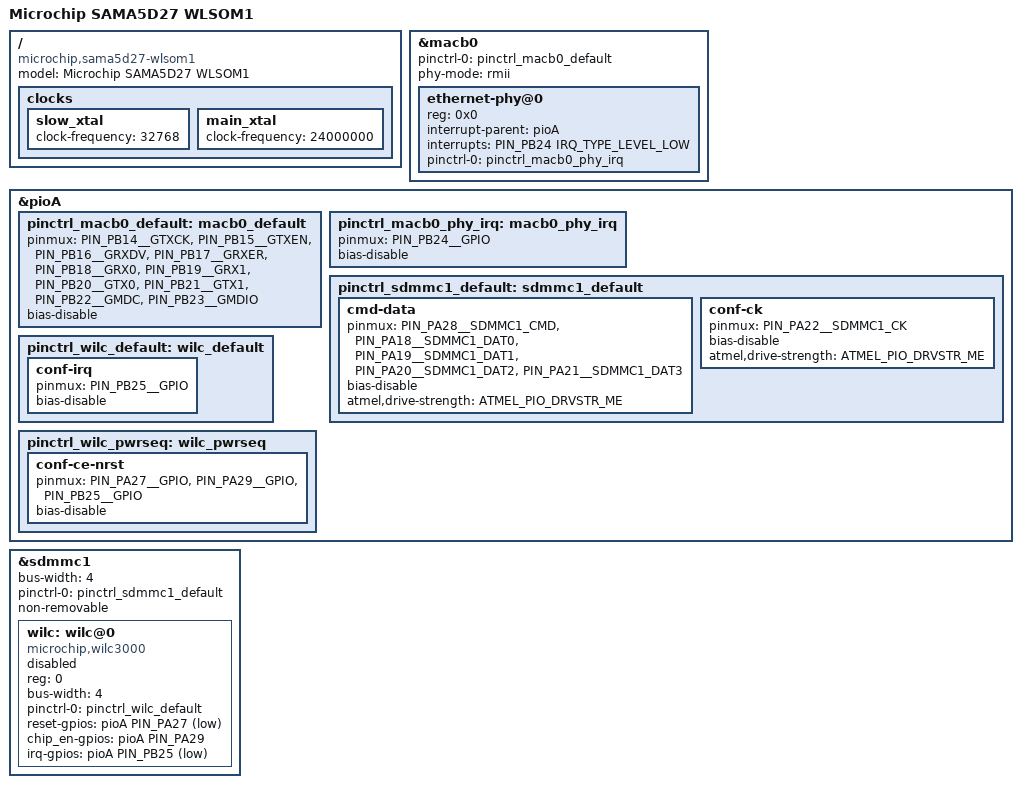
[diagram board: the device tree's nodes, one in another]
// SPDX-License-Identifier: (GPL-2.0+ OR MIT)
/*
 * at91-sama5d27_wlsom1.dtsi - Device Tree file for SAMA5D27 WLSOM1
 *
 * Copyright (C) 2019 Microchip Technology Inc. and its subsidiaries
 *
 * Author: Nicolas Ferre <nicolas.ferre@microcihp.com>
 */
#include "sama5d2.dtsi"
#include "sama5d2-pinfunc.h"
#include <dt-bindings/gpio/gpio.h>
#include <dt-bindings/pinctrl/at91.h>

/ {
	model = "Microchip SAMA5D27 WLSOM1";
	compatible = "microchip,sama5d27-wlsom1", "atmel,sama5d27", "atmel,sama5d2", "atmel,sama5";

	clocks {
		slow_xtal {
			clock-frequency = <32768>;
		};

		main_xtal {
			clock-frequency = <24000000>;
		};
	};
};

&macb0 {
	pinctrl-names = "default";
	pinctrl-0 = <&pinctrl_macb0_default>;
	phy-mode = "rmii";

	ethernet-phy@0 {
		reg = <0x0>;
		interrupt-parent = <&pioA>;
		interrupts = <PIN_PB24 IRQ_TYPE_LEVEL_LOW>;
		pinctrl-names = "default";
		pinctrl-0 = <&pinctrl_macb0_phy_irq>;
	};
};

&pioA {
	pinctrl_macb0_default: macb0_default {
		pinmux = <PIN_PB14__GTXCK>,
			 <PIN_PB15__GTXEN>,
			 <PIN_PB16__GRXDV>,
			 <PIN_PB17__GRXER>,
			 <PIN_PB18__GRX0>,
			 <PIN_PB19__GRX1>,
			 <PIN_PB20__GTX0>,
			 <PIN_PB21__GTX1>,
			 <PIN_PB22__GMDC>,
			 <PIN_PB23__GMDIO>;
		bias-disable;
	};

	pinctrl_macb0_phy_irq: macb0_phy_irq {
		pinmux = <PIN_PB24__GPIO>;
		bias-disable;
	};

	pinctrl_sdmmc1_default: sdmmc1_default {
		cmd-data {
			pinmux = <PIN_PA28__SDMMC1_CMD>,
				 <PIN_PA18__SDMMC1_DAT0>,
				 <PIN_PA19__SDMMC1_DAT1>,
				 <PIN_PA20__SDMMC1_DAT2>,
				 <PIN_PA21__SDMMC1_DAT3>;
			bias-disable;
			atmel,drive-strength = <ATMEL_PIO_DRVSTR_ME>;
		};

		conf-ck {
			pinmux = <PIN_PA22__SDMMC1_CK>;
			bias-disable;
			atmel,drive-strength = <ATMEL_PIO_DRVSTR_ME>;
		};
	};

	pinctrl_wilc_default: wilc_default {
		conf-irq {
			pinmux = <PIN_PB25__GPIO>;
			bias-disable;
		};
	};

	pinctrl_wilc_pwrseq: wilc_pwrseq {
		conf-ce-nrst {
			pinmux = <PIN_PA27__GPIO>,
				<PIN_PA29__GPIO>,
				<PIN_PB25__GPIO>;
			bias-disable;
		};
	};
};

&sdmmc1 {
	#address-cells = <1>;
	#size-cells = <0>;
	bus-width = <4>;
	pinctrl-names = "default";
	pinctrl-0 = <&pinctrl_sdmmc1_default>;
	non-removable;

	wilc: wilc@0 {
		reg = <0>;
		bus-width = <4>;
		compatible = "microchip,wilc3000", "microchip,wilc1000";
		pinctrl-names = "default";
		pinctrl-0 = <&pinctrl_wilc_default>;
		reset-gpios = <&pioA PIN_PA27 GPIO_ACTIVE_LOW>;
		chip_en-gpios = <&pioA PIN_PA29  GPIO_ACTIVE_HIGH>;
		irq-gpios = <&pioA PIN_PB25 GPIO_ACTIVE_LOW>;
		status = "disabled";
	};
};
